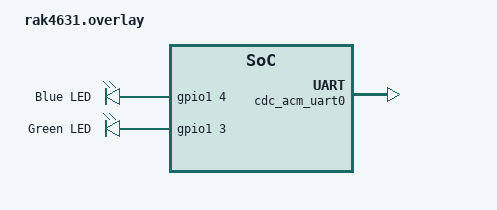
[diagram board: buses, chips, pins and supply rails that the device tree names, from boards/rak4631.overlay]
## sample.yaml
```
sample:
  name: LoRa Shell
tests:
  sample.lora.lora_shell:
    platform_allow:
      - rak3112/esp32s3/procpu
      - rak3172
      - rak4631
      - rak11160
      - rak11720
    tags: rak
    build_only: true
```

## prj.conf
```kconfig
CONFIG_GPIO=y
CONFIG_SPI=y

CONFIG_MAIN_STACK_SIZE=2048
CONFIG_SYSTEM_WORKQUEUE_STACK_SIZE=2048
CONFIG_BOOT_BANNER=n

# Serial
CONFIG_SERIAL=y
CONFIG_CONSOLE=y

# Lora
CONFIG_LORA=y
CONFIG_LORA_SHELL=y

# Shell settings
CONFIG_SHELL=y
CONFIG_SHELL_BACKEND_SERIAL=y
CONFIG_SHELL_LOG_BACKEND=n

# Logging
CONFIG_LOG=y
CONFIG_LOG_PRINTK=n
# Open following lines to
# use RTT logging for debug!!!
# CONFIG_USE_SEGGER_RTT=y
# CONFIG_LOG_BACKEND_RTT=y
# CONFIG_LOG_BACKEND_UART=n
```

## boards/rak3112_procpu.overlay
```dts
/ {
	aliases {
		blue-led = &blue_led;
		green-led = &green_led;
	};
};
```

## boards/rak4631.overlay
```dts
/ {
	chosen {
		zephyr,console = &cdc_acm_uart0;
	};

	aliases {
		blue-led = &blue_led;
		green-led = &green_led;
	};

	leds {
		compatible = "gpio-leds";
		blue_led: led_2 {
			gpios = <&gpio1 4 GPIO_ACTIVE_HIGH>;
			label = "Blue LED";
		};
		green_led: led_1 {
			gpios = <&gpio1 3 GPIO_ACTIVE_HIGH>;
			label = "Green LED";
		};
	};
};

&zephyr_udc0 {
	cdc_acm_uart0: cdc_acm_uart0 {
		compatible = "zephyr,cdc-acm-uart";
	};
};
```

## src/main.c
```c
#include <zephyr/kernel.h>
#include <zephyr/drivers/gpio.h>

#include <zephyr/logging/log.h>
LOG_MODULE_REGISTER(main, LOG_LEVEL_DBG);

/* 1000 msec = 1 sec */
#define SLEEP_TIME_MS 1000

/*
 * Get LED GPIO
 */
static const struct gpio_dt_spec led = GPIO_DT_SPEC_GET(DT_ALIAS(green_led), gpios);

static void led_init()
{
	if (!gpio_is_ready_dt(&led)) {
		LOG_ERR("LED is not ready!");
		return;
	}

	int ret = gpio_pin_configure_dt(&led, GPIO_OUTPUT_ACTIVE);
	if (ret) {
		LOG_ERR("Failed to configure LED!");
	}

	ret = gpio_pin_set_dt(&led, 1); // ON
	if (ret) {
		LOG_ERR("Failed to control LED!");
	}
	k_msleep(1000);
	ret = gpio_pin_set_dt(&led, 0); // OFF
	if (ret) {
		LOG_ERR("Failed to control LED!");
	}

	ret = gpio_pin_configure_dt(&led, GPIO_DISCONNECTED);
	if (ret) {
		LOG_ERR("Failed to disconnect LED!");
	}
}

int main(void)
{
	led_init();

	LOG_INF("LoRa Shell! %s", CONFIG_BOARD);

	return 0;
}
```

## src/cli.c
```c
#include <zephyr/kernel.h>
#include <zephyr/device.h>
#include <zephyr/shell/shell.h>
#include <zephyr/sys/printk.h>

static int cmd_test_example(const struct shell *shell, size_t argc, char *argv[])
{
	shell_print(shell, "Board: %s", CONFIG_BOARD);
	return 0;
}

SHELL_STATIC_SUBCMD_SET_CREATE(test_cmds,

			       SHELL_CMD_ARG(test, NULL, "trigger a test command", cmd_test_example,
					     0 /* mandatory param */, 0 /* optional param */),

			       SHELL_SUBCMD_SET_END);

SHELL_CMD_REGISTER(rak, &test_cmds, "RAKwireless", NULL);
```
